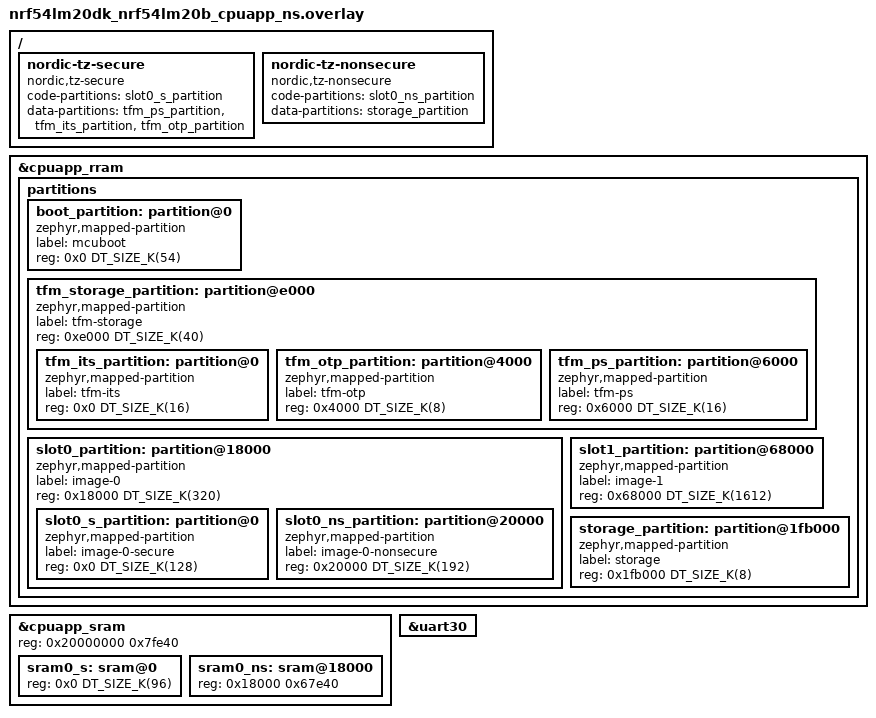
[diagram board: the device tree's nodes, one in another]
/*
 * Copyright (c) 2026 Nordic Semiconductor ASA
 *
 * SPDX-License-Identifier: LicenseRef-Nordic-5-Clause
 */

/delete-node/ &slot0_partition;
/delete-node/ &storage_partition;
/delete-node/ &tfm_ps_partition;
/delete-node/ &tfm_its_partition;
/delete-node/ &tfm_otp_partition;

&cpuapp_rram {
	partitions {
		ranges;
		#address-cells = <1>;
		#size-cells = <1>;

		boot_partition: partition@0 {
			compatible = "zephyr,mapped-partition";
			label = "mcuboot";
			reg = <0x0 DT_SIZE_K(54)>;
		};

		tfm_storage_partition: partition@e000 {
			compatible = "zephyr,mapped-partition";
			label = "tfm-storage";
			reg = <0xe000 DT_SIZE_K(40)>;
			ranges = <0x0 0xe000 DT_SIZE_K(40)>;
			#address-cells = <1>;
			#size-cells = <1>;

			tfm_its_partition: partition@0 {
				compatible = "zephyr,mapped-partition";
				label = "tfm-its";
				reg = <0x0 DT_SIZE_K(16)>;
			};

			tfm_otp_partition: partition@4000 {
				compatible = "zephyr,mapped-partition";
				label = "tfm-otp";
				reg = <0x4000 DT_SIZE_K(8)>;
			};

			tfm_ps_partition: partition@6000 {
				compatible = "zephyr,mapped-partition";
				label = "tfm-ps";
				reg = <0x6000 DT_SIZE_K(16)>;
			};
		};

		slot0_partition: partition@18000 {
			compatible = "zephyr,mapped-partition";
			label = "image-0";
			reg = <0x18000 DT_SIZE_K(320)>;
			ranges = <0x0 0x18000 DT_SIZE_K(320)>;
			#address-cells = <1>;
			#size-cells = <1>;
		};

		slot1_partition: partition@68000 {
			compatible = "zephyr,mapped-partition";
			label = "image-1";
			reg = <0x68000 DT_SIZE_K(1612)>;
		};

		storage_partition: partition@1fb000 {
			compatible = "zephyr,mapped-partition";
			label = "storage";
			reg = <0x1fb000 DT_SIZE_K(8)>;
		};
	};
};

/delete-node/ &sram0_s;
/delete-node/ &sram0_ns;

&cpuapp_sram {
	reg = <0x20000000 0x7fe40>;
	ranges = <0x0 0x20000000 0x7fe40>;

	sram0_s: sram@0 {
		reg = <0x0 DT_SIZE_K(96)>;
	};

	sram0_ns: sram@18000 {
		reg = <0x18000 0x67e40>;
	};
};

/delete-node/ &slot0_ns_partition;

&slot0_partition {
	slot0_s_partition: partition@0 {
		compatible = "zephyr,mapped-partition";
		label = "image-0-secure";
		reg = <0x0 DT_SIZE_K(128)>;
	};

	slot0_ns_partition: partition@20000 {
		compatible = "zephyr,mapped-partition";
		label = "image-0-nonsecure";
		reg = <0x20000 DT_SIZE_K(192)>;
	};
};

&uart30 {
	status = "okay";
};

/ {
	/delete-node/ nordic-tz-secure;
	/delete-node/ nordic-tz-nonsecure;

	nordic-tz-secure {
		compatible = "nordic,tz-secure";
		code-partitions = <&slot0_s_partition>;
		data-partitions = <&tfm_ps_partition>,
				  <&tfm_its_partition>,
				  <&tfm_otp_partition>;
	};

	nordic-tz-nonsecure {
		compatible = "nordic,tz-nonsecure";
		code-partitions = <&slot0_ns_partition>;
		data-partitions = <&storage_partition>;
	};
};
